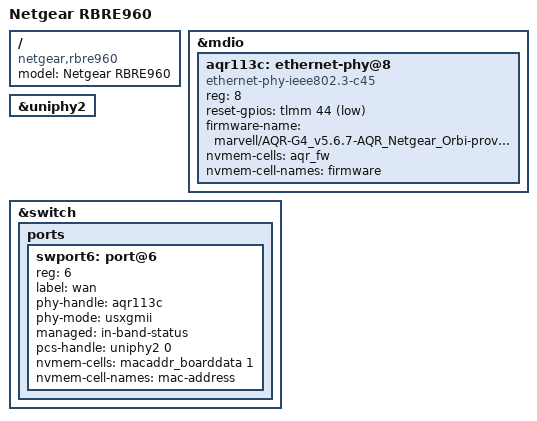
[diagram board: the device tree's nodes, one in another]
// SPDX-License-Identifier: GPL-2.0-or-later OR MIT

/dts-v1/;

#include "ipq8074-rbxe960.dtsi"

/ {
	model = "Netgear RBRE960";
	compatible = "netgear,rbre960", "qcom,ipq8074";
};

&mdio {
	aqr113c: ethernet-phy@8 {
		compatible = "ethernet-phy-ieee802.3-c45";
		reg = <8>;
		reset-gpios = <&tlmm 44 GPIO_ACTIVE_LOW>;
		firmware-name = "marvell/AQR-G4_v5.6.7-AQR_Netgear_Orbi-prov2_ID45586_VER1990.cld";
		nvmem-cells = <&aqr_fw>;
		nvmem-cell-names = "firmware";
	};
};

&uniphy2 {
	status = "okay";
};

&switch {
	ports {
		swport6: port@6 {
			reg = <6>;
			label = "wan";
			phy-handle = <&aqr113c>;
			phy-mode = "usxgmii";
			managed = "in-band-status";
			pcs-handle = <&uniphy2 0>;
			nvmem-cells = <&macaddr_boarddata 1>;
			nvmem-cell-names = "mac-address";
		};
	};
};
